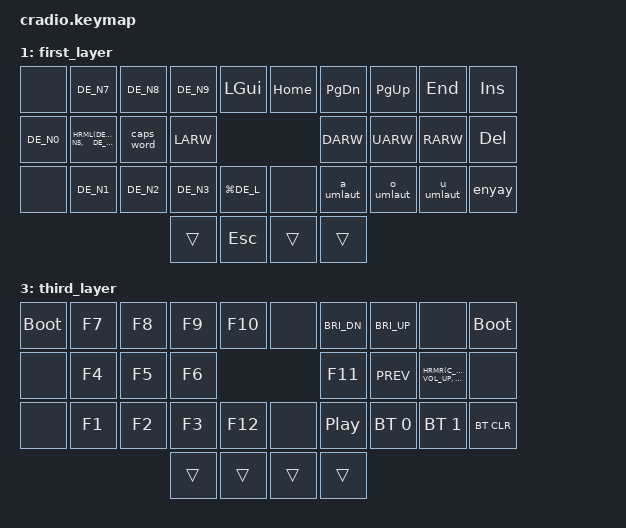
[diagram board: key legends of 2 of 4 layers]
// Copyright (c) 2022 The ZMK Contributors
// SPDX-License-Identifier: MIT

#include <behaviors.dtsi>
#include <dt-bindings/zmk/keys.h>
#include <dt-bindings/zmk/bt.h>

#include "keys_de_swiss.h"

// Home row mods macro
#define HRML(k1,k2,k3) &ht LALT k1  &ht LSHFT k2  &ht LCTRL k3
#define HRMR(k1,k2,k3) &ht LCTRL k1  &ht LSHFT k2  &ht LALT k3

&caps_word {
    continue-list = <DE_MINUS BSPC DEL>;
};

/ {
    behaviors {
        ht: hold_tap {
            label = "hold_tap";
            compatible = "zmk,behavior-hold-tap";
            #binding-cells = <2>;
            flavor = "tap-preferred";
            tapping-term-ms = <220>;
            quick-tap-ms = <150>;
            global-quick-tap;
            bindings = <&kp>, <&kp>;
        };
        slash: slash_mod {
            compatible = "zmk,behavior-mod-morph";
            label = "slash_mod";
            #binding-cells = <0>;
            bindings = <&kp DE_FSLH>, <&kp DE_BSLH>;
            mods = <(MOD_LSFT)>;
        };
        space: space_mod {
            compatible = "zmk,behavior-mod-morph";
            label = "space_mod";
            #binding-cells = <0>;
            bindings = <&kp DE_SPACE>, <&kp TAB>;
            mods = <(MOD_LSFT)>;
        };
        back: back_mod {
            compatible = "zmk,behavior-mod-morph";
            label = "back_mod";
            #binding-cells = <0>;
            bindings = <&kp BSPC>, <&kp DEL>;
            mods = <(MOD_LSFT)>;
        };
        a_umlaut: a_umlaut_mod {
            compatible = "zmk,behavior-mod-morph";
            label = "a_umlaut_mod";
            #binding-cells = <0>;
            bindings = <&diacritic DE_UMLAUT DE_A>, <&diacritic DE_UMLAUT LS(DE_A)>;
            mods = <(MOD_LSFT)>;
        };
        o_umlaut: o_umlaut_mod {
            compatible = "zmk,behavior-mod-morph";
            label = "o_umlaut_mod";
            #binding-cells = <0>;
            bindings = <&diacritic DE_UMLAUT DE_O>, <&diacritic DE_UMLAUT LS(DE_O)>;
            mods = <(MOD_LSFT)>;
        };
        u_umlaut: u_umlaut_mod {
            compatible = "zmk,behavior-mod-morph";
            label = "u_umlaut_mod";
            #binding-cells = <0>;
            bindings = <&diacritic DE_UMLAUT DE_U>, <&diacritic DE_UMLAUT LS(DE_U)>;
            mods = <(MOD_LSFT)>;
        };
        enyay: enyay_mod {
            compatible = "zmk,behavior-mod-morph";
            label = "enyay_mod";
            #binding-cells = <0>;
            bindings = <&diacritic DE_TILDE DE_N>, <&diacritic DE_TILDE LS(DE_N)>;
            mods = <(MOD_LSFT)>;
        };
    };

    macros {
        db: double_macro {
            label = "double_macro";
            compatible = "zmk,behavior-macro-one-param";
            wait-ms = <10>;
            tap-ms = <10>;
            #binding-cells = <1>;
            bindings
                = <&macro_param_1to1>
                , <&kp MACRO_PLACEHOLDER>
                , <&macro_param_1to1>
                , <&kp MACRO_PLACEHOLDER>;
        };
        diacritic: diacritic_macro {
            label = "diacritic_macro";
            compatible = "zmk,behavior-macro-two-param";
            wait-ms = <10>;
            tap-ms = <10>;
            #binding-cells = <2>;
            bindings
                = <&macro_param_1to1>
                , <&kp MACRO_PLACEHOLDER>
                , <&macro_param_2to1>
                , <&kp MACRO_PLACEHOLDER>
                ;
        };
        inv_qmark: inv_qmark_macro {
            label = "inv_qmark_macro";
            compatible = "zmk,behavior-macro";
            wait-ms = <10>;
            tap-ms = <10>;
            #binding-cells = <0>;
            bindings
                = <&macro_tap &kp RCTRL &kp DE_QMARK &kp DE_QMARK>;
        };
        inv_excl: inv_excl_macro {
            label = "inv_excl_macro";
            compatible = "zmk,behavior-macro";
            wait-ms = <10>;
            tap-ms = <10>;
            #binding-cells = <0>;
            bindings
                = <&macro_tap &kp RCTRL &kp DE_EXCL &kp DE_EXCL>;
        };
    };

    conditional_layers {
        compatible = "zmk,conditional-layers";
        tri_layer {
            if-layers = <1 2>;
            then-layer = <3>;
        };
    };

    keymap {
        compatible = "zmk,keymap";
        default_layer {
            bindings = <
        //╭──────────┬──────────┬──────────┬──────────┬──────────╮   ╭──────────┬──────────┬──────────┬──────────┬──────────╮
        //│  Q       │  W       │  E       │  R       │  T       │   │  Z       │  U       │  I       │  O       │  P       │
            &kp DE_Q   &kp DE_W   &kp DE_E   &kp DE_R   &kp DE_T       &kp DE_Z   &kp DE_U   &kp DE_I   &kp DE_O   &kp DE_P
        //├──────────┼──────────┼──────────┼──────────┼──────────┤   ├──────────┼──────────┼──────────┼──────────┼──────────┤
        //│  A       │  S       │  D       │  F       │  G       │   │  H       │  J       │  K       │  L       │ / \      │
            &kp DE_A  HRML(DE_S,   DE_D,      DE_F)     &kp DE_G       &kp DE_H  HRMR(DE_J,   DE_K,      DE_L)     &slash
        //├──────────┼──────────┼──────────┼──────────┼──────────┤   ├──────────┼──────────┼──────────┼──────────┼──────────┤
        //│  Y       │  X       │  C       │  V       │  B       │   │  N       │  M       │ , ;      │ . :      │ - _      │
            &kp DE_Y   &kp DE_X   &kp DE_C   &kp DE_V   &kp DE_B     &kp DE_N   &kp DE_M &kp DE_COMMA &kp DE_DOT &kp DE_MINUS
        //╰──────────┴──────────┴──────────┼──────────┼──────────┤   ├──────────┼──────────┼──────────┴──────────┴──────────╯
                                            &lt 2 TAB &kp DE_SPACE     &kp BSPC  &lt 1 ENTER
        //                                 ╰──────────┴──────────╯   ╰──────────┴──────────╯
            >;
        };

        first_layer {
            bindings = <
        //╭──────────┬──────────┬──────────┬──────────┬──────────╮   ╭──────────┬──────────┬──────────┬──────────┬──────────╮
        //│          │  7       │  8       │  9       │ GUI      │   │ HOME     │ PAGE DN  │ PAGE UP  │ END      │ INSERT   │
            &none      &kp DE_N7  &kp DE_N8  &kp DE_N9  &kp LGUI       &kp HOME   &kp PG_DN  &kp PG_UP  &kp END    &kp INS
        //├──────────┼──────────┼──────────┼──────────┼──────────┤   ├──────────┼──────────┼──────────┼──────────┼──────────┤
        //│  0       │  4       │  5       │  6       │ CAPS     │   │ LEFT     │ DOWN     │ UP       │ RIGHT    │ DELETE   │
            &kp DE_N0 HRML(DE_N4,  DE_N5,     DE_N6)   &caps_word      &kp LARW   &kp DARW   &kp UARW   &kp RARW   &kp DEL
        //├──────────┼──────────┼──────────┼──────────┼──────────┤   ├──────────┼──────────┼──────────┼──────────┼──────────┤
        //│          │  1       │  2       │  3       │ LOCK     │   │          │  ä       │  ö       │  ü       │  ñ       │
            &none      &kp DE_N1  &kp DE_N2  &kp DE_N3 &kp LG(DE_L)    &none      &a_umlaut  &o_umlaut  &u_umlaut  &enyay
        //╰──────────┴──────────┴──────────┼──────────┼──────────┤   ├──────────┼──────────┼──────────┴──────────┴──────────╯
                                             &trans     &kp ESC        &trans     &trans
        //                                 ╰──────────┴──────────╯   ╰──────────┴──────────╯
            >;
        };

        second_layer {
            bindings = <
        //╭──────────┬──────────┬──────────┬──────────┬──────────╮   ╭──────────┬──────────┬──────────┬──────────┬──────────╮
        //│  °       │  ?       │  {       │  }       │  ¿       │   │  ^       │  (       │  )       │  $       │          │
     &kp LS(DE_SECT) &kp DE_QMARK &kp DE_LBRC &kp DE_RBRC &inv_qmark &db DE_CARET &kp DE_LPAR &kp DE_RPAR &kp DE_DLLR &none
        //├──────────┼──────────┼──────────┼──────────┼──────────┤   ├──────────┼──────────┼──────────┼──────────┼──────────┤
        //│  |       │  @       │  &       │  #       │  %       │   │  +       │  *       │  =       │  '       │  "       │
         &kp DE_PIPE  HRML(DE_AT, DE_AMPS,   DE_HASH) &kp DE_PRCNT   &kp DE_PLUS HRMR(DE_STAR, DE_EQUAL, DE_SQT)  &kp DE_DQT
        //├──────────┼──────────┼──────────┼──────────┼──────────┤   ├──────────┼──────────┼──────────┼──────────┼──────────┤
        //│ ¨        │  !       │  <       │  >       │  ¡       │   │  ~       │  [       │  ]       │  ´       │  `       │
         &db DE_UMLAUT &kp DE_EXCL &kp DE_LT &kp DE_GT  &inv_excl  &db DE_TILDE &kp DE_LBKT &kp DE_RBKT &db DE_ACUTE &db DE_GRAVE
        //╰──────────┴──────────┴──────────┼──────────┼──────────┤   ├──────────┼──────────┼──────────┴──────────┴──────────╯
                                             &trans     &trans         &kp DEL    &trans
        //                                 ╰──────────┴──────────╯   ╰──────────┴──────────╯
            >;
        };

        third_layer {
            bindings = <
        //╭──────────┬──────────┬──────────┬──────────┬──────────╮   ╭──────────┬──────────┬──────────┬──────────┬──────────╮
        //│BOOTLOADER│ F7       │ F8       │ F9       │ F10      │   │          │ DARKER   │ BRIGHTER │          │BOOTLOADER│
          &bootloader  &kp F7     &kp F8     &kp F9     &kp F10        &none   &kp C_BRI_DN &kp C_BRI_UP &none   &bootloader
        //├──────────┼──────────┼──────────┼──────────┼──────────┤   ├──────────┼──────────┼──────────┼──────────┼──────────┤
        //│          │ F4       | F5       | F6       │ F11      │   │ PREVIOUS │ QUIETER  │ LOUDER   │ NEXT     │          │
            &none      &kp F4     &kp F5     &kp F6     &kp F11     &kp C_PREV HRMR(C_VOL_DN, C_VOL_UP, C_NEXT)    &none 
        //├──────────┼──────────┼──────────┼──────────┼──────────┤   ├──────────┼──────────┼──────────┼──────────┼──────────┤
        //│          │ F1       │ F2       │ F3       │ F12      │   │          │PLAY/PAUSE│PROFILE 0 │PROFILE 1 │ CLEAR BT │
            &none      &kp F1     &kp F2     &kp F3     &kp F12        &none    &kp C_PP &bt BT_SEL 0 &bt BT_SEL 1 &bt BT_CLR
        //╰──────────┴──────────┴──────────┼──────────┼──────────┤   ├──────────┼──────────┼──────────┴──────────┴──────────╯
                                             &trans     &trans         &trans     &trans
        //                                 ╰──────────┴──────────╯   ╰──────────┴──────────╯
            >;
        };
    };
};
